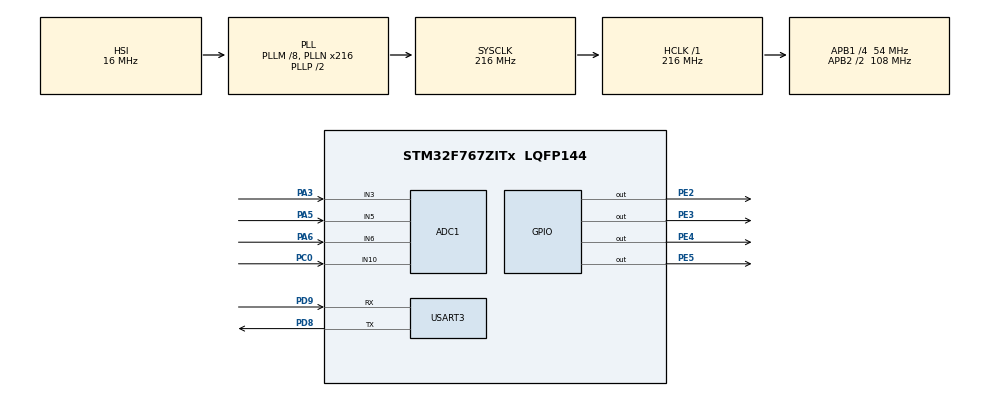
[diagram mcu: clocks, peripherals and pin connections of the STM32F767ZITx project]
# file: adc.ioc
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ADC1.Channel-0\#ChannelRegularConversion=ADC_CHANNEL_10
ADC1.ContinuousConvMode=ENABLE
ADC1.EOCSelection=ADC_EOC_SEQ_CONV
ADC1.NbrOfConversionFlag=1
ADC1.Rank-0\#ChannelRegularConversion=1
ADC1.SamplingTime-0\#ChannelRegularConversion=ADC_SAMPLETIME_3CYCLES
ADC1.master=1
CORTEX_M7.default_mode_Activation=1
Dma.ADC1.0.Direction=DMA_PERIPH_TO_MEMORY
Dma.ADC1.0.FIFOMode=DMA_FIFOMODE_DISABLE
Dma.ADC1.0.Instance=DMA2_Stream0
Dma.ADC1.0.MemDataAlignment=DMA_MDATAALIGN_HALFWORD
Dma.ADC1.0.MemInc=DMA_MINC_ENABLE
Dma.ADC1.0.Mode=DMA_NORMAL
Dma.ADC1.0.PeriphDataAlignment=DMA_PDATAALIGN_HALFWORD
Dma.ADC1.0.PeriphInc=DMA_PINC_DISABLE
Dma.ADC1.0.Priority=DMA_PRIORITY_LOW
Dma.Request0=ADC1
Mcu.Family=STM32F7
Mcu.Name=STM32F767ZITx
Mcu.Package=LQFP144
NVIC.DMA2_Stream0_IRQn=true\:0\:0\:false\:false\:true\:false\:true\:true
NVIC.PriorityGroup=NVIC_PRIORITYGROUP_4
PA3.Signal=ADCx_IN3
PA5.Signal=ADCx_IN5
PA6.Signal=ADCx_IN6
PC0.Signal=ADCx_IN10
PD8.Mode=Asynchronous
PD8.Signal=USART3_TX
PD9.Mode=Asynchronous
PD9.Signal=USART3_RX
PE2.Signal=GPIO_Output
PE3.Signal=GPIO_Output
PE4.Signal=GPIO_Output
PE5.Signal=GPIO_Output
ProjectManager.HeapSize=0x200
ProjectManager.StackSize=0x400
ProjectManager.TargetToolchain=STM32CubeIDE
RCC.AHBFreq_Value=216000000
RCC.APB1CLKDivider=RCC_HCLK_DIV4
RCC.APB1Freq_Value=54000000
RCC.APB1TimFreq_Value=108000000
RCC.APB2CLKDivider=RCC_HCLK_DIV2
RCC.APB2Freq_Value=108000000
RCC.APB2TimFreq_Value=216000000
RCC.CortexFreq_Value=216000000
RCC.HCLKFreq_Value=216000000
RCC.HSE_VALUE=25000000
RCC.HSI_VALUE=16000000
RCC.LSE_VALUE=32768
RCC.PLLM=8
RCC.PLLN=216
RCC.SYSCLKFreq_VALUE=216000000
RCC.SYSCLKSource=RCC_SYSCLKSOURCE_PLLCLK
RCC.USBFreq_Value=216000000
RCC.VCOOutputFreq_Value=432000000
SH.ADCx_IN10.0=ADC1_IN10,IN10
SH.ADCx_IN3.0=ADC1_IN3,IN3
SH.ADCx_IN5.0=ADC1_IN5,IN5
SH.ADCx_IN6.0=ADC1_IN6,IN6
USART3.VirtualMode-Asynchronous=VM_ASYNC
board=custom

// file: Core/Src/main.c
/* USER CODE BEGIN Header */
/**
  ******************************************************************************
  * @file           : main.c
  * @brief          : Main program body
  ******************************************************************************
  * @attention
  *
  * Copyright (c) 2024 STMicroelectronics.
  * All rights reserved.
  *
  * This software is licensed under terms that can be found in the LICENSE file
  * in the root directory of this software component.
  * If no LICENSE file comes with this software, it is provided AS-IS.
  *
  ******************************************************************************
  */
/* USER CODE END Header */
#include "main.h"
#include "adc.h"
#include "usart.h"
#include "gpio.h"
#include "string.h"
#include "stdio.h"
#include "dma.h"

/* USER CODE BEGIN PV */
volatile uint32_t adc_val = 0;
uint32_t adc_val_buffer[1];
/* USER CODE END PV */

void SystemClock_Config(void);
static void MPU_Config(void);

/* USER CODE BEGIN 0 */
//void displayHEX(uint32_t value){
//
//}

int average_16(int x) {
    static int samples[16];
    static int i = 0;
    static int total = 0;

    /* Update the moving average */
    total += x - samples[i];
    samples[i] = x;

    /* Update the index */
    i = (i == 15 ? 0 : i + 1);

    return total >> 4; // Divide by 16
}
/* USER CODE END 0 */

int main(void)
{

  /* MPU Configuration--------------------------------------------------------*/
  MPU_Config();

  /* MCU Configuration--------------------------------------------------------*/

  /* Reset of all peripherals, Initializes the Flash interface and the Systick. */
  HAL_Init();

  /* Configure the system clock */
  SystemClock_Config();

  /* Initialize all configured peripherals */
  MX_GPIO_Init();
  MX_ADC1_Init();
  MX_USART3_UART_Init();
  MX_DMA_Init();
  /* USER CODE BEGIN 2 */
  HAL_ADC_Start_DMA(&hadc1, adc_val_buffer, 1);
  /* USER CODE END 2 */

  /* Infinite loop */
  while (1)
  {
	  while(HAL_ADC_PollForConversion(&hadc1, 100) != HAL_OK){}
	  adc_val = HAL_ADC_GetValue(&hadc1);
	  HAL_ADC_Start_DMA(&hadc1, adc_val_buffer, 1);
	  adc_val = average_16(adc_val);
	  char uartBuffer[50];
	  sprintf(uartBuffer, "Integer: %lu\r\n", adc_val);
	  HAL_UART_Transmit(&huart3, (uint8_t*)uartBuffer, strlen(uartBuffer), HAL_MAX_DELAY);
	  if(adc_val >= 0 && adc_val <= 819){
		  HAL_GPIO_WritePin(GPIOE, GPIO_PIN_2|GPIO_PIN_3|GPIO_PIN_4|GPIO_PIN_5, GPIO_PIN_SET);
	  }
	  if( adc_val >= 819 && adc_val <= 1638 ){
		  HAL_GPIO_WritePin(GPIOE, GPIO_PIN_2, GPIO_PIN_RESET);
	  }
	  if( adc_val >= 1638 && adc_val <= 2457 ){
		  HAL_GPIO_WritePin(GPIOE, GPIO_PIN_3, GPIO_PIN_RESET);
	  }
	  if( adc_val >= 2457 && adc_val <= 3276 ){
		  HAL_GPIO_WritePin(GPIOE, GPIO_PIN_4, GPIO_PIN_RESET);
	  }
	  if( adc_val >= 3276 && adc_val <= 4095 ){
		  HAL_GPIO_WritePin(GPIOE, GPIO_PIN_5, GPIO_PIN_RESET);
	  }
  }
}

void SystemClock_Config(void)
{
  RCC_OscInitTypeDef RCC_OscInitStruct = {0};
  RCC_ClkInitTypeDef RCC_ClkInitStruct = {0};

  /** Configure the main internal regulator output voltage
  */
  __HAL_RCC_PWR_CLK_ENABLE();
  __HAL_PWR_VOLTAGESCALING_CONFIG(PWR_REGULATOR_VOLTAGE_SCALE1);

  /** Initializes the RCC Oscillators according to the specified parameters
  * in the RCC_OscInitTypeDef structure.
  */
  RCC_OscInitStruct.OscillatorType = RCC_OSCILLATORTYPE_HSI;
  RCC_OscInitStruct.HSIState = RCC_HSI_ON;
  RCC_OscInitStruct.HSICalibrationValue = RCC_HSICALIBRATION_DEFAULT;
  RCC_OscInitStruct.PLL.PLLState = RCC_PLL_ON;
  RCC_OscInitStruct.PLL.PLLSource = RCC_PLLSOURCE_HSI;
  RCC_OscInitStruct.PLL.PLLM = 8;
  RCC_OscInitStruct.PLL.PLLN = 216;
  RCC_OscInitStruct.PLL.PLLP = RCC_PLLP_DIV2;
  RCC_OscInitStruct.PLL.PLLQ = 2;
  RCC_OscInitStruct.PLL.PLLR = 2;
  if (HAL_RCC_OscConfig(&RCC_OscInitStruct) != HAL_OK)
  {
    Error_Handler();
  }

  /** Activate the Over-Drive mode
  */
  if (HAL_PWREx_EnableOverDrive() != HAL_OK)
  {
    Error_Handler();
  }

  /** Initializes the CPU, AHB and APB buses clocks
  */
  RCC_ClkInitStruct.ClockType = RCC_CLOCKTYPE_HCLK|RCC_CLOCKTYPE_SYSCLK
                              |RCC_CLOCKTYPE_PCLK1|RCC_CLOCKTYPE_PCLK2;
  RCC_ClkInitStruct.SYSCLKSource = RCC_SYSCLKSOURCE_PLLCLK;
  RCC_ClkInitStruct.AHBCLKDivider = RCC_SYSCLK_DIV1;
  RCC_ClkInitStruct.APB1CLKDivider = RCC_HCLK_DIV4;
  RCC_ClkInitStruct.APB2CLKDivider = RCC_HCLK_DIV2;

  if (HAL_RCC_ClockConfig(&RCC_ClkInitStruct, FLASH_LATENCY_7) != HAL_OK)
  {
    Error_Handler();
  }
}

 /* MPU Configuration */

void MPU_Config(void)
{
  MPU_Region_InitTypeDef MPU_InitStruct = {0};

  /* Disables the MPU */
  HAL_MPU_Disable();

  /** Initializes and configures the Region and the memory to be protected
  */
  MPU_InitStruct.Enable = MPU_REGION_ENABLE;
  MPU_InitStruct.Number = MPU_REGION_NUMBER0;
  MPU_InitStruct.BaseAddress = 0x0;
  MPU_InitStruct.Size = MPU_REGION_SIZE_4GB;
  MPU_InitStruct.SubRegionDisable = 0x87;
  MPU_InitStruct.TypeExtField = MPU_TEX_LEVEL0;
  MPU_InitStruct.AccessPermission = MPU_REGION_NO_ACCESS;
  MPU_InitStruct.DisableExec = MPU_INSTRUCTION_ACCESS_DISABLE;
  MPU_InitStruct.IsShareable = MPU_ACCESS_SHAREABLE;
  MPU_InitStruct.IsCacheable = MPU_ACCESS_NOT_CACHEABLE;
  MPU_InitStruct.IsBufferable = MPU_ACCESS_NOT_BUFFERABLE;

  HAL_MPU_ConfigRegion(&MPU_InitStruct);
  /* Enables the MPU */
  HAL_MPU_Enable(MPU_PRIVILEGED_DEFAULT);

}

void Error_Handler(void)
{
  __disable_irq();
  while (1)
  {
  }
}
